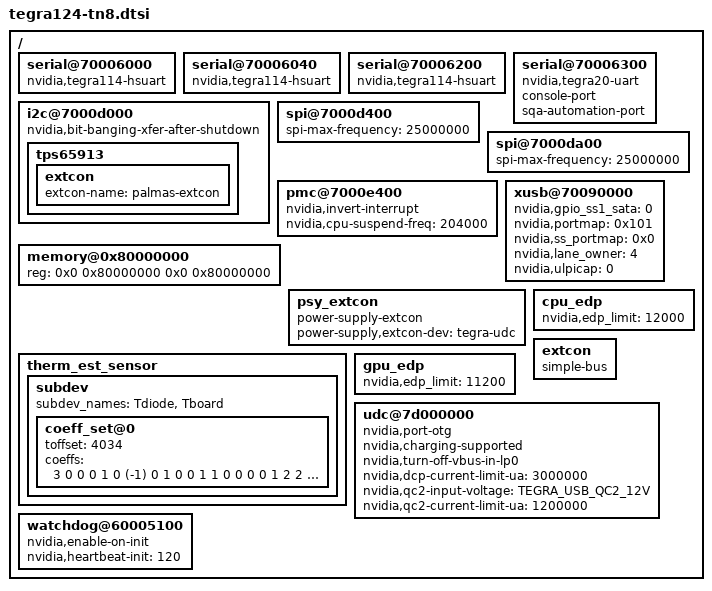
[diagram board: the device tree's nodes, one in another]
/*
 * arch/arm/boot/dts/tegra124-tn8.dtsi
 *
 * Copyright (c) 2013-2015, NVIDIA CORPORATION.  All rights reserved.
 *
 * This program is free software; you can redistribute it and/or modify
 * it under the terms of the GNU General Public License as published by
 * the Free Software Foundation; either version 2 of the License, or
 * (at your option) any later version.
 *
 * This program is distributed in the hope that it will be useful, but WITHOUT
 * ANY WARRANTY; without even the implied warranty of MERCHANTABILITY or
 * FITNESS FOR A PARTICULAR PURPOSE.  See the GNU General Public License for
 * more details.
 *
 * You should have received a copy of the GNU General Public License along
 * with this program; if not, write to the Free Software Foundation, Inc.,
 * 51 Franklin Street, Fifth Floor, Boston, MA  02110-1301, USA.
 */

#include "tegra124-soc-shield.dtsi"
#include "tegra124-platforms/tegra124-modem-common.dtsi"

/ {
	serial@70006000 {
		compatible = "nvidia,tegra114-hsuart";
		status = "okay";
	};

	serial@70006040 {
		compatible = "nvidia,tegra114-hsuart";
		status = "okay";
	};

	serial@70006200 {
		compatible = "nvidia,tegra114-hsuart";
		status = "okay";
	};

	serial@70006300 {
		compatible = "nvidia,tegra20-uart", "nvidia,tegra114-hsuart";
		console-port;
		sqa-automation-port;
		status = "okay";
	};

	i2c@7000d000 {
		nvidia,bit-banging-xfer-after-shutdown;

		tps65913 {
			extcon {
				extcon-name = "palmas-extcon";
			};
		};
	};

	spi@7000d400 {
		status = "okay";
		spi-max-frequency = <25000000>;
	};

	spi@7000da00 {
		status = "okay";
		spi-max-frequency = <25000000>;
	};

	pmc@7000e400 {
		status = "okay";
		nvidia,invert-interrupt;
		nvidia,cpu-suspend-freq = <204000>;
	};

	xusb@70090000 {
		/* nvidia,uses_external_pmic;
		nvidia,gpio_controls_muxed_ss_lanes; */
		nvidia,gpio_ss1_sata = <0>;
		nvidia,portmap = <0x101>; /* SSP0, USB2P0 */
		nvidia,ss_portmap = <0x0>; /* SSP0 on USB2P0 */
		nvidia,lane_owner = <4>; /* USB3P0 */
		nvidia,ulpicap = <0>; /* No ulpi support. can we remove */
		status = "okay";
	};

	memory@0x80000000 {
		device_type = "memory";
		reg = <0x0 0x80000000 0x0 0x80000000>;
	};

	psy_extcon {
		compatible = "power-supply-extcon";
		power-supply,extcon-dev = "tegra-udc";
	};

	therm_est_sensor {
		subdev {
			subdev_names = "Tdiode", "Tboard";

			coeff_set@0 {
				toffset = <4034>;
				coeffs = <
					3 0 0 0 1 0 (-1) 0 1 0 0 1 1 0 0 0 0 1 2 2
					1 1 2 8 6 (-8) (-13) (-9) (-9) (-8) (-17) (-18) (-18) (-16) 2 17 15 27 42 60
				>;
			};
		};
	};

	cpu_edp {
		nvidia,edp_limit = <12000>;
	};

	extcon {
		compatible = "simple-bus";
		device_type = "external-connection";
		#address-cells = <1>;
		#size-cells = <0>;
	};

	gpu_edp {
		nvidia,edp_limit = <11200>;
	};

	udc@7d000000 {
		nvidia,port-otg;
		nvidia,charging-supported;
		nvidia,turn-off-vbus-in-lp0;
		nvidia,dcp-current-limit-ua = <3000000>;
		nvidia,qc2-input-voltage = <TEGRA_USB_QC2_12V>;
		nvidia,qc2-current-limit-ua = <1200000>;
	};

	watchdog@60005100 {
		nvidia,enable-on-init;
		nvidia,heartbeat-init = <120>;
	};
};
